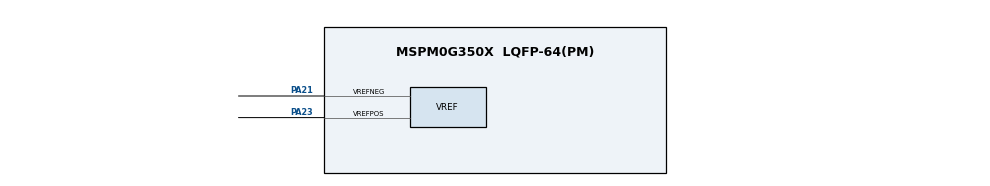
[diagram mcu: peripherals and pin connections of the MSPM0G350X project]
// @cliArgs --device "MSPM0G350X" --package "LQFP-64(PM)" --part "Default"
// @cliArgs --board /ti/boards/LP_MSPM0G3507 --rtos nortos

/**
 * Import the modules used in this configuration.
 */
const DAC12  = scripting.addModule("/ti/driverlib/DAC12");
const SYSCTL = scripting.addModule("/ti/driverlib/SYSCTL");
const VREF   = scripting.addModule("/ti/driverlib/VREF");

/**
 * Write custom configuration values to the imported modules.
 */
const gate8  = system.clockTree["MFPCLKGATE"];
gate8.enable = true;

DAC12.dacOutputPinEn = true;
DAC12.dacAmplifier   = "ON";
DAC12.dacPosVREF     = "VEREFP";
DAC12.dacNegVREF     = "VEREFN";

const Board = scripting.addModule("/ti/driverlib/Board", {}, false);

SYSCTL.MFPCLKEn    = true;
SYSCTL.forceDefaultClkConfig = true;
SYSCTL.clockTreeEn  = true;

VREF.basicVrefPins                 = "VREF+-";
VREF.basicIntVolt                  = "DL_VREF_BUFCONFIG_OUTPUT_2_5V";
VREF.checkVREFReady                = true;
VREF.advClockConfigEnable          = true;
VREF.advClkSrc                     = "DL_VREF_CLOCK_BUSCLK";
VREF.peripheral.$assign            = "VREF";
VREF.peripheral.vrefPosPin.$assign = "PA23";
VREF.peripheral.vrefNegPin.$assign = "PA21";
